# CSI2PHY_SCP register map
Vendor: Texas Instruments
Peripheral module from a debugger description file (folder omap34xx).
Registers are 32-bit, read-write, reset 0x427 unless marked. A register's access mark holds for its fields unless they carry their own. Offsets are as the file gives them; lines under a group give offsets from that group; [hi:lo] are bit positions; {n}, {i} and the like mark numbered series; 'fields as' and 'values as' point back to an identical list; <NAME> marks a mode.

## CSI2PHY_SCP
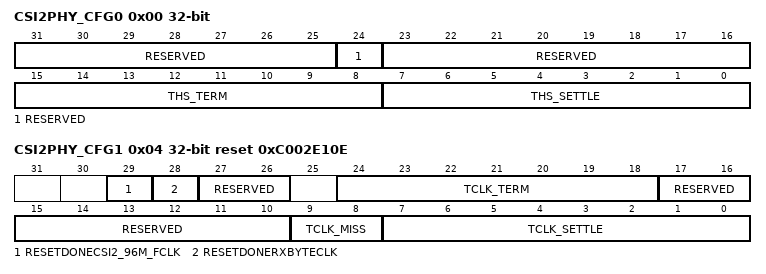
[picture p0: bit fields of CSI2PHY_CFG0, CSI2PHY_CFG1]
0x00 CSI2PHY_CFG0 — Configuration register for Ths-term Ths-settle
  [31:25] RESERVED — Write only 0 for future compatibility.
  [24] RESERVED — Write only 0 for future compatibility.
  [23:16] RESERVED — Write only 0 for future compatibility.
  [15:8] THS_TERM — Ths-term timing parameter in multiples of CSI2_96M_FCLK period.Requirement from DSI_PHY spec = (Dn Voltage 450 mV) - 35 ns + 4 UI.Effective time for enabling termination = synchoniser delay + timer delay + LPRx delay + combinatorial routing delay ~ (1-2)*DDRCLK + Ths-term + ~ (1-15) ns.Programmed value = ceil(12.5 ns/DDRClk period)-1).Default value: 4 for 400 MHz. 20% clock frequency tolerance.
  [7:0] THS_SETTLE — Ths-settle timing parameter in multiples of DDR clock period.Derived requirement from DSI_PHY spec = (90 ns + 6 UI) - (145 ns + 10 UI).Effective Ths-settle seen on the line (starting to look for sync pattern) = synchoniser delay + timer delay + LPRx delay + combinatorial routing delay - pipeline delay in HS data path.~ (1-2)*DDRCLK + Ths-settle + ~ (1-15) ns - 1*DDRClkProgrammed value = ceil(90 ns/DDR clock period)+3. Default value: 39 for 400 MHz. (1) Minimum supported Ths-settle preprogrammed value = 3. (2) One clock delay in datapath from HSRx needs to be compensated. Hence + 3.
0x04 CSI2PHY_CFG1 access per field reset 0xC002E10E (reset mask 0xCDFFFFFF) — Configuration register for Tclk-term, Tclk-settle Tclk-miss. Reset done status for the CLKIN4DDR clock domains.
  [29] RESETDONECSI2_96M_FCLK ro — Reset Done flag for the CSI2_96M_FCLK domainRead 0x0: Reset in progressRead 0x1: Reset completed
  [28] RESETDONERXBYTECLK ro — Reset Done flag for the RxByteClkHS clock domainRead 0x0: Reset in progressRead 0x1: Reset completed
  [27:26] RESERVED ro — Read returns 0. Write only 0 for future compatibility.
  [24:18] TCLK_TERM rw — Tclk-term timing parameter in multiples of CSI2_96M_FCLK period.Requirement from DSI_PHY spec = (Dn Voltage 450 mV) - 55 ns.Effective time for enabling termination = synchonizer delay + timer delay + LPRx delay + combinatorial routing delay ~ (1-2)*CSI2_96M_FCLK + Tclk-term + ~ (1-15) ns. Programmed value = ceil(9.5 ns/CSI2_96M_FCLK period)-1).Default value: 0 for 96 MHz. 5% clock frequency tolerance.
  [17:10] RESERVED rw — Must be written with reset value
  [9:8] TCLK_MISS rw — Tclk-miss timing parameter in multiples of CSI2_96M_FCLK periodProgrammed value = ceil(15 ns/CSI2_96M_FCLK period)-1Default value: 1 for 96 MHz
  [7:0] TCLK_SETTLE rw — Tclk-settle timing parameter in multiples of CSI2_96M_FCLK period.Derived requirement from DSI_PHY spec = 145 ns - 435 ns.Effective Ths-settle = synchonizer delay + timer delay + LPRx delay + combinatorial routing delay ~ (1-2)*CSI2_96M_FCLK + Tclk-settle + ~ (1-15) ns. Programmed value = max(3, ceil(155 ns/CSI2_96M_FCLK period)-1).Default value: 14 for 96 MHz. 5% clock frequency tolerance.
